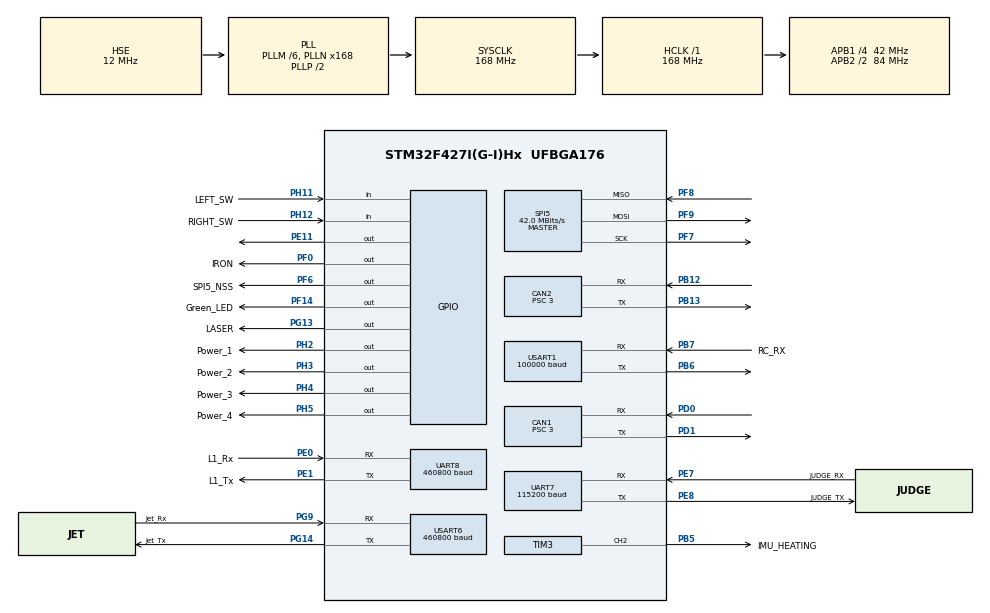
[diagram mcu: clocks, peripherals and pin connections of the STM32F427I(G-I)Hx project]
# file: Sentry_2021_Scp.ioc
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CAN1.BS1=CAN_BS1_9TQ
CAN1.BS2=CAN_BS2_4TQ
CAN1.CalculateTimeQuantum=71.42857142857143
CAN1.Prescaler=3
CAN2.BS1=CAN_BS1_9TQ
CAN2.BS2=CAN_BS2_4TQ
CAN2.CalculateTimeQuantum=71.42857142857143
CAN2.Prescaler=3
Dma.Request0=USART6_RX
Dma.Request1=UART8_RX
Dma.Request2=UART7_RX
Dma.Request3=UART7_TX
Dma.Request4=USART1_RX
Dma.Request5=USART6_TX
Dma.Request6=UART8_TX
Dma.UART7_RX.2.Direction=DMA_PERIPH_TO_MEMORY
Dma.UART7_RX.2.FIFOMode=DMA_FIFOMODE_DISABLE
Dma.UART7_RX.2.Instance=DMA1_Stream3
Dma.UART7_RX.2.MemDataAlignment=DMA_MDATAALIGN_BYTE
Dma.UART7_RX.2.MemInc=DMA_MINC_ENABLE
Dma.UART7_RX.2.Mode=DMA_CIRCULAR
Dma.UART7_RX.2.PeriphDataAlignment=DMA_PDATAALIGN_BYTE
Dma.UART7_RX.2.PeriphInc=DMA_PINC_DISABLE
Dma.UART7_RX.2.Priority=DMA_PRIORITY_LOW
Dma.UART7_TX.3.Direction=DMA_MEMORY_TO_PERIPH
Dma.UART7_TX.3.FIFOMode=DMA_FIFOMODE_DISABLE
Dma.UART7_TX.3.Instance=DMA1_Stream1
Dma.UART7_TX.3.MemDataAlignment=DMA_MDATAALIGN_BYTE
Dma.UART7_TX.3.MemInc=DMA_MINC_ENABLE
Dma.UART7_TX.3.Mode=DMA_NORMAL
Dma.UART7_TX.3.PeriphDataAlignment=DMA_PDATAALIGN_BYTE
Dma.UART7_TX.3.PeriphInc=DMA_PINC_DISABLE
Dma.UART7_TX.3.Priority=DMA_PRIORITY_LOW
Dma.UART8_RX.1.Direction=DMA_PERIPH_TO_MEMORY
Dma.UART8_RX.1.FIFOMode=DMA_FIFOMODE_DISABLE
Dma.UART8_RX.1.Instance=DMA1_Stream6
Dma.UART8_RX.1.MemDataAlignment=DMA_MDATAALIGN_BYTE
Dma.UART8_RX.1.MemInc=DMA_MINC_ENABLE
Dma.UART8_RX.1.Mode=DMA_CIRCULAR
Dma.UART8_RX.1.PeriphDataAlignment=DMA_PDATAALIGN_BYTE
Dma.UART8_RX.1.PeriphInc=DMA_PINC_DISABLE
Dma.UART8_RX.1.Priority=DMA_PRIORITY_LOW
Dma.UART8_TX.6.Direction=DMA_MEMORY_TO_PERIPH
Dma.UART8_TX.6.FIFOMode=DMA_FIFOMODE_DISABLE
Dma.UART8_TX.6.Instance=DMA1_Stream0
Dma.UART8_TX.6.MemDataAlignment=DMA_MDATAALIGN_BYTE
Dma.UART8_TX.6.MemInc=DMA_MINC_ENABLE
Dma.UART8_TX.6.Mode=DMA_NORMAL
Dma.UART8_TX.6.PeriphDataAlignment=DMA_PDATAALIGN_BYTE
Dma.UART8_TX.6.PeriphInc=DMA_PINC_DISABLE
Dma.UART8_TX.6.Priority=DMA_PRIORITY_LOW
Dma.USART1_RX.4.Direction=DMA_PERIPH_TO_MEMORY
Dma.USART1_RX.4.FIFOMode=DMA_FIFOMODE_DISABLE
Dma.USART1_RX.4.Instance=DMA2_Stream2
Dma.USART1_RX.4.MemDataAlignment=DMA_MDATAALIGN_BYTE
Dma.USART1_RX.4.MemInc=DMA_MINC_ENABLE
Dma.USART1_RX.4.Mode=DMA_CIRCULAR
Dma.USART1_RX.4.PeriphDataAlignment=DMA_PDATAALIGN_BYTE
Dma.USART1_RX.4.PeriphInc=DMA_PINC_DISABLE
Dma.USART1_RX.4.Priority=DMA_PRIORITY_LOW
Dma.USART6_RX.0.Direction=DMA_PERIPH_TO_MEMORY
Dma.USART6_RX.0.FIFOMode=DMA_FIFOMODE_DISABLE
Dma.USART6_RX.0.Instance=DMA2_Stream1
Dma.USART6_RX.0.MemDataAlignment=DMA_MDATAALIGN_BYTE
Dma.USART6_RX.0.MemInc=DMA_MINC_ENABLE
Dma.USART6_RX.0.Mode=DMA_CIRCULAR
Dma.USART6_RX.0.PeriphDataAlignment=DMA_PDATAALIGN_BYTE
Dma.USART6_RX.0.PeriphInc=DMA_PINC_DISABLE
Dma.USART6_RX.0.Priority=DMA_PRIORITY_LOW
Dma.USART6_TX.5.Direction=DMA_MEMORY_TO_PERIPH
Dma.USART6_TX.5.FIFOMode=DMA_FIFOMODE_DISABLE
Dma.USART6_TX.5.Instance=DMA2_Stream6
Dma.USART6_TX.5.MemDataAlignment=DMA_MDATAALIGN_BYTE
Dma.USART6_TX.5.MemInc=DMA_MINC_ENABLE
Dma.USART6_TX.5.Mode=DMA_NORMAL
Dma.USART6_TX.5.PeriphDataAlignment=DMA_PDATAALIGN_BYTE
Dma.USART6_TX.5.PeriphInc=DMA_PINC_DISABLE
Dma.USART6_TX.5.Priority=DMA_PRIORITY_LOW
FREERTOS.INCLUDE_pcTaskGetTaskName=1
FREERTOS.INCLUDE_uxTaskGetStackHighWaterMark=1
FREERTOS.INCLUDE_vTaskDelayUntil=1
FREERTOS.Tasks01=defaultTask,0,128,Task_Init,As weak,NULL,Dynamic,NULL,NULL
Mcu.Family=STM32F4
Mcu.Name=STM32F427I(G-I)Hx
Mcu.Package=UFBGA176
NVIC.CAN1_RX0_IRQn=true\:5\:0\:true\:false\:true\:true\:true\:true
NVIC.CAN2_RX1_IRQn=true\:5\:0\:true\:false\:true\:true\:true\:true
NVIC.DMA1_Stream0_IRQn=true\:0\:0\:false\:false\:true\:true\:false\:true
NVIC.DMA1_Stream1_IRQn=true\:0\:0\:false\:false\:true\:true\:false\:true
NVIC.DMA1_Stream3_IRQn=true\:0\:0\:false\:false\:true\:true\:false\:true
NVIC.DMA1_Stream6_IRQn=true\:0\:0\:false\:false\:true\:true\:false\:true
NVIC.DMA2_Stream1_IRQn=true\:0\:0\:false\:false\:true\:true\:false\:true
NVIC.DMA2_Stream2_IRQn=true\:0\:0\:false\:false\:true\:true\:false\:true
NVIC.DMA2_Stream6_IRQn=true\:0\:0\:false\:false\:true\:true\:false\:true
NVIC.PriorityGroup=NVIC_PRIORITYGROUP_4
NVIC.TIM2_IRQn=true\:0\:0\:false\:false\:true\:false\:false\:true
NVIC.TimeBase=TIM2_IRQn
NVIC.TimeBaseIP=TIM2
NVIC.UART7_IRQn=true\:5\:0\:true\:false\:true\:false\:true\:true
NVIC.UART8_IRQn=true\:5\:0\:true\:false\:true\:true\:true\:true
NVIC.USART1_IRQn=true\:5\:0\:true\:false\:true\:false\:true\:true
NVIC.USART6_IRQn=true\:5\:0\:true\:false\:true\:true\:true\:true
PA13.Mode=Trace_Asynchronous_SW
PA13.Signal=SYS_JTMS-SWDIO
PA14.Mode=Trace_Asynchronous_SW
PA14.Signal=SYS_JTCK-SWCLK
PB12.Mode=Slave
PB12.Signal=CAN2_RX
PB13.Mode=Slave
PB13.Signal=CAN2_TX
PB3.Mode=Trace_Asynchronous_SW
PB3.Signal=SYS_JTDO-SWO
PB5.GPIO_Label=IMU_HEATING
PB5.Signal=S_TIM3_CH2
PB6.Mode=Asynchronous
PB6.Signal=USART1_TX
PB7.GPIO_Label=RC_RX
PB7.Mode=Asynchronous
PB7.Signal=USART1_RX
PD0.Mode=Master
PD0.Signal=CAN1_RX
PD1.Mode=Master
PD1.Signal=CAN1_TX
PE0.GPIO_Label=L1_Rx
PE0.Mode=Asynchronous
PE0.Signal=UART8_RX
PE1.GPIO_Label=L1_Tx
PE1.Mode=Asynchronous
PE1.Signal=UART8_TX
PE11.Signal=GPIO_Output
PE7.GPIO_Label=JUDGE_RX
PE7.Mode=Asynchronous
PE7.Signal=UART7_RX
PE8.GPIO_Label=JUDGE_TX
PE8.Mode=Asynchronous
PE8.Signal=UART7_TX
PF0.GPIO_Label=IRON
PF0.Signal=GPIO_Output
PF14.GPIO_Label=Green_LED
PF14.Signal=GPIO_Output
PF6.GPIO_Label=SPI5_NSS
PF6.GPIO_Speed=GPIO_SPEED_FREQ_LOW
PF6.Signal=GPIO_Output
PF7.Mode=Full_Duplex_Master
PF7.Signal=SPI5_SCK
PF8.Mode=Full_Duplex_Master
PF8.Signal=SPI5_MISO
PF9.Mode=Full_Duplex_Master
PF9.Signal=SPI5_MOSI
PG13.GPIO_Label=LASER
PG13.Signal=GPIO_Output
PG14.GPIO_Label=Jet_Tx
PG14.Mode=Asynchronous
PG14.Signal=USART6_TX
PG9.GPIO_Label=Jet_Rx
PG9.Mode=Asynchronous
PG9.Signal=USART6_RX
PH0/OSC_IN.Mode=HSE-External-Oscillator
PH0/OSC_IN.Signal=RCC_OSC_IN
PH1/OSC_OUT.Mode=HSE-External-Oscillator
PH1/OSC_OUT.Signal=RCC_OSC_OUT
PH11.GPIO_Label=LEFT_SW
PH11.Signal=GPIO_Input
PH12.GPIO_Label=RIGHT_SW
PH12.Signal=GPIO_Input
PH2.GPIO_Label=Power_1
PH2.PinState=GPIO_PIN_SET
PH2.Signal=GPIO_Output
PH3.GPIO_Label=Power_2
PH3.PinState=GPIO_PIN_SET
PH3.Signal=GPIO_Output
PH4.GPIO_Label=Power_3
PH4.PinState=GPIO_PIN_SET
PH4.Signal=GPIO_Output
PH5.GPIO_Label=Power_4
PH5.PinState=GPIO_PIN_SET
PH5.Signal=GPIO_Output
ProjectManager.HeapSize=0x200
ProjectManager.StackSize=0x400
ProjectManager.TargetToolchain=MDK-ARM V5
RCC.48MHZClocksFreq_Value=84000000
RCC.AHBFreq_Value=168000000
RCC.APB1CLKDivider=RCC_HCLK_DIV4
RCC.APB1Freq_Value=42000000
RCC.APB1TimFreq_Value=84000000
RCC.APB2CLKDivider=RCC_HCLK_DIV2
RCC.APB2Freq_Value=84000000
RCC.APB2TimFreq_Value=168000000
RCC.CortexFreq_Value=168000000
RCC.HCLKFreq_Value=168000000
RCC.HSE_VALUE=12000000
RCC.HSI_VALUE=16000000
RCC.LSE_VALUE=32768
RCC.PLLM=6
RCC.PLLN=168
RCC.PLLSourceVirtual=RCC_PLLSOURCE_HSE
RCC.SYSCLKFreq_VALUE=168000000
RCC.SYSCLKSource=RCC_SYSCLKSOURCE_PLLCLK
RCC.VCOOutputFreq_Value=336000000
SH.S_TIM3_CH2.0=TIM3_CH2,PWM Generation2 CH2
SPI5.CalculateBaudRate=42.0 MBits/s
SPI5.Direction=SPI_DIRECTION_2LINES
SPI5.Mode=SPI_MODE_MASTER
SPI5.VirtualType=VM_MASTER
TIM3.Channel-PWM\ Generation2\ CH2=TIM_CHANNEL_2
TIM3.Period=2000-1
TIM3.Prescaler=84-1
UART7.BaudRate=115200
UART7.VirtualMode=Asynchronous
UART8.BaudRate=460800
UART8.VirtualMode=Asynchronous
USART1.BaudRate=100000
USART1.Parity=PARITY_EVEN
USART1.VirtualMode=VM_ASYNC
USART1.WordLength=WORDLENGTH_9B
USART6.BaudRate=460800
USART6.VirtualMode=VM_ASYNC
VP_FREERTOS_VS_CMSIS_V1.Mode=CMSIS_V1
VP_SYS_VS_tim2.Mode=TIM2
board=custom

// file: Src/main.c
/* USER CODE BEGIN Header */
/**
  ******************************************************************************
  * @file           : main.c
  * @brief          : Main program body
  ******************************************************************************
  * @attention
  *
  * <h2><center>&copy; Copyright (c) 2020 STMicroelectronics.
  * All rights reserved.</center></h2>
  *
  * This software component is licensed by ST under Ultimate Liberty license
  * SLA0044, the "License"; You may not use this file except in compliance with
  * the License. You may obtain a copy of the License at:
  *                             www.st.com/SLA0044
  *
  ******************************************************************************
  */
/* USER CODE END Header */
#include "main.h"
#include "cmsis_os.h"
#include "can.h"
#include "dma.h"
#include "spi.h"
#include "tim.h"
#include "usart.h"
#include "gpio.h"

void SystemClock_Config(void);
void MX_FREERTOS_Init(void);

int main(void)
{

  /* MCU Configuration--------------------------------------------------------*/

  /* Reset of all peripherals, Initializes the Flash interface and the Systick. */
  HAL_Init();

  /* USER CODE BEGIN Init */
	//HAL_Delay(9000);
  /* USER CODE END Init */

  /* Configure the system clock */
  SystemClock_Config();

  /* Initialize all configured peripherals */
  MX_GPIO_Init();
  MX_DMA_Init();
  MX_CAN1_Init();
  MX_USART6_UART_Init();
  MX_CAN2_Init();
  MX_UART8_Init();
  MX_SPI5_Init();
  MX_TIM3_Init();
  MX_UART7_Init();
  MX_USART1_UART_Init();

  /* Call init function for freertos objects (in freertos.c) */
  MX_FREERTOS_Init();
  /* Start scheduler */
  osKernelStart();

  /* We should never get here as control is now taken by the scheduler */
  /* Infinite loop */
  while (1)
  {

  }
}

void SystemClock_Config(void)
{
  RCC_OscInitTypeDef RCC_OscInitStruct = {0};
  RCC_ClkInitTypeDef RCC_ClkInitStruct = {0};

  /** Configure the main internal regulator output voltage
  */
  __HAL_RCC_PWR_CLK_ENABLE();
  __HAL_PWR_VOLTAGESCALING_CONFIG(PWR_REGULATOR_VOLTAGE_SCALE1);
  /** Initializes the RCC Oscillators according to the specified parameters
  * in the RCC_OscInitTypeDef structure.
  */
  RCC_OscInitStruct.OscillatorType = RCC_OSCILLATORTYPE_HSE;
  RCC_OscInitStruct.HSEState = RCC_HSE_ON;
  RCC_OscInitStruct.PLL.PLLState = RCC_PLL_ON;
  RCC_OscInitStruct.PLL.PLLSource = RCC_PLLSOURCE_HSE;
  RCC_OscInitStruct.PLL.PLLM = 6;
  RCC_OscInitStruct.PLL.PLLN = 168;
  RCC_OscInitStruct.PLL.PLLP = RCC_PLLP_DIV2;
  RCC_OscInitStruct.PLL.PLLQ = 4;
  if (HAL_RCC_OscConfig(&RCC_OscInitStruct) != HAL_OK)
  {
    Error_Handler();
  }
  /** Initializes the CPU, AHB and APB buses clocks
  */
  RCC_ClkInitStruct.ClockType = RCC_CLOCKTYPE_HCLK|RCC_CLOCKTYPE_SYSCLK
                              |RCC_CLOCKTYPE_PCLK1|RCC_CLOCKTYPE_PCLK2;
  RCC_ClkInitStruct.SYSCLKSource = RCC_SYSCLKSOURCE_PLLCLK;
  RCC_ClkInitStruct.AHBCLKDivider = RCC_SYSCLK_DIV1;
  RCC_ClkInitStruct.APB1CLKDivider = RCC_HCLK_DIV4;
  RCC_ClkInitStruct.APB2CLKDivider = RCC_HCLK_DIV2;

  if (HAL_RCC_ClockConfig(&RCC_ClkInitStruct, FLASH_LATENCY_5) != HAL_OK)
  {
    Error_Handler();
  }
}

void HAL_TIM_PeriodElapsedCallback(TIM_HandleTypeDef *htim)
{
  if (htim->Instance == TIM2) {
    HAL_IncTick();
  }
}

void Error_Handler(void)
{
}

/************************ (C) COPYRIGHT STMicroelectronics *****END OF FILE****/

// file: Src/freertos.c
/* USER CODE BEGIN Header */
/**
  ******************************************************************************
  * File Name          : freertos.c
  * Description        : Code for freertos applications
  ******************************************************************************
  * @attention
  *
  * <h2><center>&copy; Copyright (c) 2020 STMicroelectronics.
  * All rights reserved.</center></h2>
  *
  * This software component is licensed by ST under Ultimate Liberty license
  * SLA0044, the "License"; You may not use this file except in compliance with
  * the License. You may obtain a copy of the License at:
  *                             www.st.com/SLA0044
  *
  ******************************************************************************
  */
/* USER CODE END Header */

#include "FreeRTOS.h"
#include "task.h"
#include "main.h"
#include "cmsis_os.h"

osThreadId defaultTaskHandle;

void Task_Init(void const * argument);

void MX_FREERTOS_Init(void); /* (MISRA C 2004 rule 8.1) */

/* GetIdleTaskMemory prototype (linked to static allocation support) */
void vApplicationGetIdleTaskMemory( StaticTask_t **ppxIdleTaskTCBBuffer, StackType_t **ppxIdleTaskStackBuffer, uint32_t *pulIdleTaskStackSize );

/* USER CODE BEGIN GET_IDLE_TASK_MEMORY */
static StaticTask_t xIdleTaskTCBBuffer;
static StackType_t xIdleStack[configMINIMAL_STACK_SIZE];

void vApplicationGetIdleTaskMemory( StaticTask_t **ppxIdleTaskTCBBuffer, StackType_t **ppxIdleTaskStackBuffer, uint32_t *pulIdleTaskStackSize )
{
  *ppxIdleTaskTCBBuffer = &xIdleTaskTCBBuffer;
  *ppxIdleTaskStackBuffer = &xIdleStack[0];
  *pulIdleTaskStackSize = configMINIMAL_STACK_SIZE;
  /* place for user code */
}
/* USER CODE END GET_IDLE_TASK_MEMORY */

void MX_FREERTOS_Init(void) {

  /* Create the thread(s) */
  /* definition and creation of defaultTask */
  osThreadDef(defaultTask, Task_Init, osPriorityNormal, 0, 128);
  defaultTaskHandle = osThreadCreate(osThread(defaultTask), NULL);

}

__weak void Task_Init(void const * argument)
{
  for(;;)
  {
    osDelay(1);
  }
}

/************************ (C) COPYRIGHT STMicroelectronics *****END OF FILE****/
